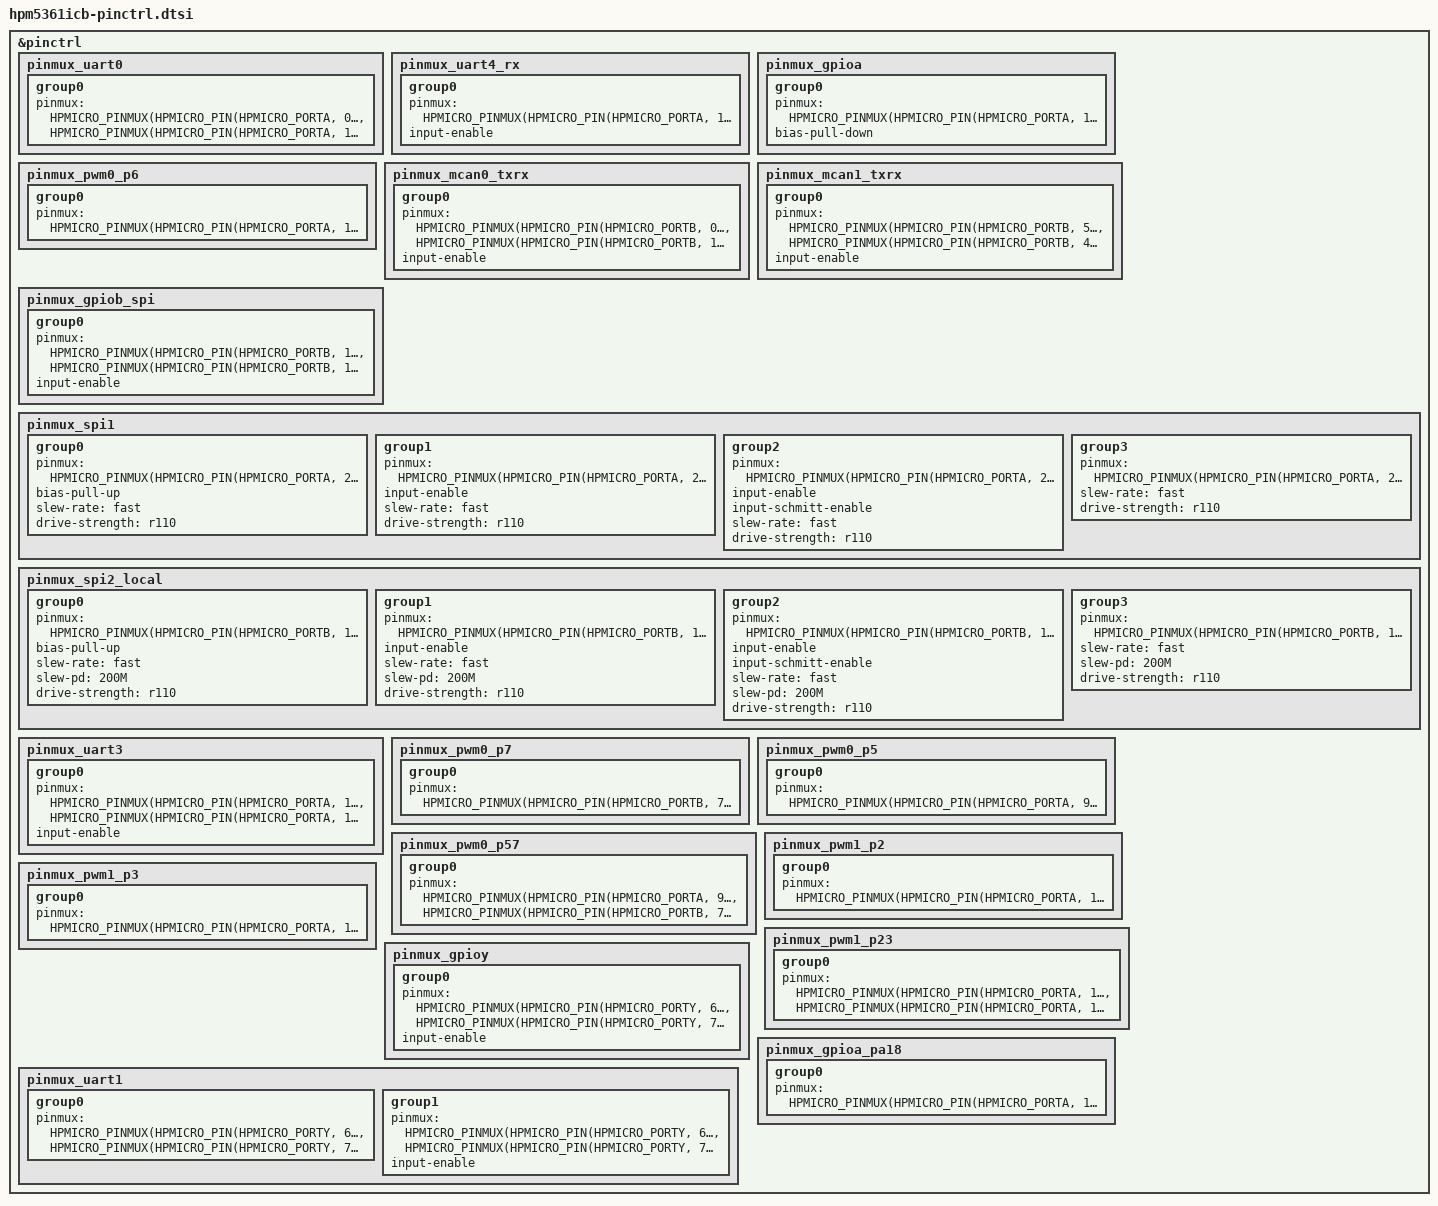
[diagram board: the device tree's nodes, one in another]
/*
 * Copyright 2025 HPMicro
 * SPDX-License-Identifier: Apache-2.0
 */

#include "dt-bindings/pinctrl/hpmicro-pinctrl-common.h"

&pinctrl {
	pinmux_uart0: pinmux_uart0 {
		group0 {
			pinmux = <HPMICRO_PINMUX(HPMICRO_PIN(HPMICRO_PORTA, 0), IOC_TYPE_IOC, 0, 2)>,
				 <HPMICRO_PINMUX(HPMICRO_PIN(HPMICRO_PORTA, 1), IOC_TYPE_IOC, 0, 2)>;
		};
	};

	pinmux_uart4_rx: pinmux_uart4_rx {
		group0 {
			pinmux = <HPMICRO_PINMUX(HPMICRO_PIN(HPMICRO_PORTA, 17), IOC_TYPE_IOC, 0, 2)>;
			input-enable;
		};
	};

	pinmux_gpioa: pinmux_gpioa {
		group0 {
			pinmux = <HPMICRO_PINMUX(HPMICRO_PIN(HPMICRO_PORTA, 10), IOC_TYPE_IOC, 0, 0)>;
			bias-pull-down;
		};
	};

	pinmux_pwm0_p6: pinmux_pwm0_p6 {
		group0 {
			pinmux = <HPMICRO_PINMUX(HPMICRO_PIN(HPMICRO_PORTA, 10), IOC_TYPE_IOC, 0, 16)>;
		};
	};

	pinmux_mcan0_txrx: pinmux_mcan0_txrx {
		group0 {
			pinmux = <HPMICRO_PINMUX(HPMICRO_PIN(HPMICRO_PORTB, 0), IOC_TYPE_IOC, 0, 7)>,
				 <HPMICRO_PINMUX(HPMICRO_PIN(HPMICRO_PORTB, 1), IOC_TYPE_IOC, 0, 7)>;
			input-enable;
		};
	};

	pinmux_mcan1_txrx: pinmux_mcan1_txrx {
		group0 {
			pinmux = <HPMICRO_PINMUX(HPMICRO_PIN(HPMICRO_PORTB, 5), IOC_TYPE_IOC, 0, 7)>,
				 <HPMICRO_PINMUX(HPMICRO_PIN(HPMICRO_PORTB, 4), IOC_TYPE_IOC, 0, 7)>;
			input-enable;
		};
	};

	pinmux_gpiob_spi: pinmux_gpiob_spi {
		group0 {
			pinmux = <HPMICRO_PINMUX(HPMICRO_PIN(HPMICRO_PORTB, 14), IOC_TYPE_IOC, 0, 0)>,
				 <HPMICRO_PINMUX(HPMICRO_PIN(HPMICRO_PORTB, 15), IOC_TYPE_IOC, 0, 0)>;
			input-enable;
		};
	};

	pinmux_spi1: pinmux_spi1 {
		group0 {
			pinmux = <HPMICRO_PINMUX(HPMICRO_PIN(HPMICRO_PORTA, 26), IOC_TYPE_IOC, 0, 5)>;
			bias-pull-up;
			slew-rate = "fast";
			drive-strength = "r110";
		};

		group1 {
			pinmux = <HPMICRO_PINMUX(HPMICRO_PIN(HPMICRO_PORTA, 27), IOC_TYPE_IOC, 0, 5)>;
			input-enable;
			slew-rate = "fast";
			drive-strength = "r110";
		};

		group2 {
			pinmux = <HPMICRO_PINMUX(HPMICRO_PIN(HPMICRO_PORTA, 28), IOC_TYPE_IOC, 0, 5)>;
			input-enable;
			input-schmitt-enable;
			slew-rate = "fast";
			drive-strength = "r110";
		};

		group3 {
			pinmux = <HPMICRO_PINMUX(HPMICRO_PIN(HPMICRO_PORTA, 29), IOC_TYPE_IOC, 0, 5)>;
			slew-rate = "fast";
			drive-strength = "r110";
		};
	};

	pinmux_spi2_local: pinmux_spi2_local {
		group0 {
			pinmux = <HPMICRO_PINMUX(HPMICRO_PIN(HPMICRO_PORTB, 10), IOC_TYPE_IOC, 0, 5)>;
			bias-pull-up;
			slew-rate = "fast";
			slew-pd = "200M";
			drive-strength = "r110";
		};

		group1 {
			pinmux = <HPMICRO_PINMUX(HPMICRO_PIN(HPMICRO_PORTB, 11), IOC_TYPE_IOC, 0, 5)>;
			input-enable;
			slew-rate = "fast";
			slew-pd = "200M";
			drive-strength = "r110";
		};

		group2 {
			pinmux = <HPMICRO_PINMUX(HPMICRO_PIN(HPMICRO_PORTB, 12), IOC_TYPE_IOC, 0, 5)>;
			input-enable;
			input-schmitt-enable;
			slew-rate = "fast";
			slew-pd = "200M";
			drive-strength = "r110";
		};

		group3 {
			pinmux = <HPMICRO_PINMUX(HPMICRO_PIN(HPMICRO_PORTB, 13), IOC_TYPE_IOC, 0, 5)>;
			slew-rate = "fast";
			slew-pd = "200M";
			drive-strength = "r110";
		};
	};

	pinmux_uart3: pinmux_uart3 {
		group0 {
			pinmux = <HPMICRO_PINMUX(HPMICRO_PIN(HPMICRO_PORTA, 14), IOC_TYPE_IOC, 0, 2)>,
				 <HPMICRO_PINMUX(HPMICRO_PIN(HPMICRO_PORTA, 15), IOC_TYPE_IOC, 0, 2)>;
			input-enable;
		};
	};

	pinmux_pwm0_p7: pinmux_pwm0_p7 {
		group0 {
			pinmux = <HPMICRO_PINMUX(HPMICRO_PIN(HPMICRO_PORTB, 7), IOC_TYPE_IOC, 0, 16)>;
		};
	};

	pinmux_pwm0_p5: pinmux_pwm0_p5 {
		group0 {
			pinmux = <HPMICRO_PINMUX(HPMICRO_PIN(HPMICRO_PORTA, 9), IOC_TYPE_IOC, 0, 16)>;
		};
	};

	pinmux_pwm0_p57: pinmux_pwm0_p57 {
		group0 {
			pinmux = <HPMICRO_PINMUX(HPMICRO_PIN(HPMICRO_PORTA, 9), IOC_TYPE_IOC, 0, 16)>,
				 <HPMICRO_PINMUX(HPMICRO_PIN(HPMICRO_PORTB, 7), IOC_TYPE_IOC, 0, 16)>;
		};
	};

	pinmux_pwm1_p2: pinmux_pwm1_p2 {
		group0 {
			pinmux = <HPMICRO_PINMUX(HPMICRO_PIN(HPMICRO_PORTA, 18), IOC_TYPE_IOC, 0, 17)>;
		};
	};

	pinmux_pwm1_p3: pinmux_pwm1_p3 {
		group0 {
			pinmux = <HPMICRO_PINMUX(HPMICRO_PIN(HPMICRO_PORTA, 19), IOC_TYPE_IOC, 0, 17)>;
		};
	};

	pinmux_pwm1_p23: pinmux_pwm1_p23 {
		group0 {
			pinmux = <HPMICRO_PINMUX(HPMICRO_PIN(HPMICRO_PORTA, 18), IOC_TYPE_IOC, 0, 17)>,
				 <HPMICRO_PINMUX(HPMICRO_PIN(HPMICRO_PORTA, 19), IOC_TYPE_IOC, 0, 17)>;
		};
	};

	pinmux_gpioy: pinmux_gpioy {
		group0 {
			pinmux = <HPMICRO_PINMUX(HPMICRO_PIN(HPMICRO_PORTY, 6), IOC_TYPE_PIOC, 0, 3)>,
				 <HPMICRO_PINMUX(HPMICRO_PIN(HPMICRO_PORTY, 7), IOC_TYPE_PIOC, 0, 3)>;
			input-enable;
		};
	};

	pinmux_uart1: pinmux_uart1 {
		group0 {
			// PIOC ALT=3: hand control to IOC
			pinmux = <HPMICRO_PINMUX(HPMICRO_PIN(HPMICRO_PORTY, 6), IOC_TYPE_PIOC, 0, 3)>,
				 <HPMICRO_PINMUX(HPMICRO_PIN(HPMICRO_PORTY, 7), IOC_TYPE_PIOC, 0, 3)>;
		};
		group1 {
			// IOC ALT=2: UART1 function
			pinmux = <HPMICRO_PINMUX(HPMICRO_PIN(HPMICRO_PORTY, 6), IOC_TYPE_IOC, 0, 2)>,
				 <HPMICRO_PINMUX(HPMICRO_PIN(HPMICRO_PORTY, 7), IOC_TYPE_IOC, 0, 2)>;
			input-enable;
		};
	};

	pinmux_gpioa_pa18: pinmux_gpioa_pa18 {
		group0 {
			pinmux = <HPMICRO_PINMUX(HPMICRO_PIN(HPMICRO_PORTA, 18), IOC_TYPE_IOC, 0, 0)>;
		};
	};
};
